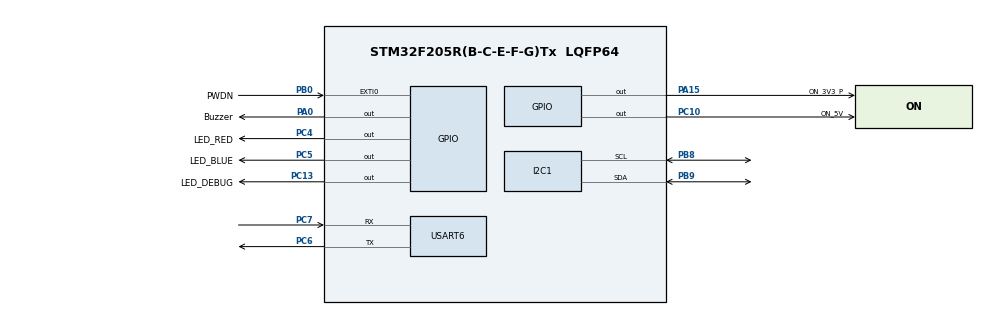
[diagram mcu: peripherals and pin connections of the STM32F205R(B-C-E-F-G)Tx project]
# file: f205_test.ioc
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Dma.Request0=USART6_RX
Dma.Request1=USART6_TX
Dma.USART6_RX.0.Direction=DMA_PERIPH_TO_MEMORY
Dma.USART6_RX.0.FIFOMode=DMA_FIFOMODE_DISABLE
Dma.USART6_RX.0.Instance=DMA2_Stream1
Dma.USART6_RX.0.MemDataAlignment=DMA_MDATAALIGN_BYTE
Dma.USART6_RX.0.MemInc=DMA_MINC_ENABLE
Dma.USART6_RX.0.Mode=DMA_NORMAL
Dma.USART6_RX.0.PeriphDataAlignment=DMA_PDATAALIGN_BYTE
Dma.USART6_RX.0.PeriphInc=DMA_PINC_DISABLE
Dma.USART6_RX.0.Priority=DMA_PRIORITY_LOW
Dma.USART6_TX.1.Direction=DMA_MEMORY_TO_PERIPH
Dma.USART6_TX.1.FIFOMode=DMA_FIFOMODE_DISABLE
Dma.USART6_TX.1.Instance=DMA2_Stream6
Dma.USART6_TX.1.MemDataAlignment=DMA_MDATAALIGN_BYTE
Dma.USART6_TX.1.MemInc=DMA_MINC_ENABLE
Dma.USART6_TX.1.Mode=DMA_NORMAL
Dma.USART6_TX.1.PeriphDataAlignment=DMA_PDATAALIGN_BYTE
Dma.USART6_TX.1.PeriphInc=DMA_PINC_DISABLE
Dma.USART6_TX.1.Priority=DMA_PRIORITY_LOW
Mcu.Family=STM32F2
Mcu.Name=STM32F205R(B-C-E-F-G)Tx
Mcu.Package=LQFP64
NVIC.DMA2_Stream1_IRQn=true\:0\:0\:false\:false\:true\:false\:true\:true
NVIC.DMA2_Stream6_IRQn=true\:0\:0\:false\:false\:true\:false\:true\:true
NVIC.EXTI0_IRQn=true\:0\:0\:false\:false\:true\:true\:true\:true
NVIC.PriorityGroup=NVIC_PRIORITYGROUP_4
PA0-WKUP.GPIO_Label=Buzzer
PA0-WKUP.Signal=GPIO_Output
PA15.GPIO_Label=ON_3V3_P
PA15.Signal=GPIO_Output
PB0.GPIO_Label=PWDN
PB0.Signal=GPXTI0
PB14.Signal=USB_OTG_HS_DM
PB15.Signal=USB_OTG_HS_DP
PB8.GPIO_Pu=GPIO_PULLUP
PB8.Mode=I2C
PB8.Signal=I2C1_SCL
PB9.GPIO_Pu=GPIO_PULLUP
PB9.Mode=I2C
PB9.Signal=I2C1_SDA
PC10.GPIO_Label=ON_5V
PC10.PinState=GPIO_PIN_SET
PC10.Signal=GPIO_Output
PC13.GPIO_Label=LED_DEBUG
PC13.Signal=GPIO_Output
PC4.GPIO_Label=LED_RED
PC4.Signal=GPIO_Output
PC5.GPIO_Label=LED_BLUE
PC5.Signal=GPIO_Output
PC6.Mode=Asynchronous
PC6.Signal=USART6_TX
PC7.Mode=Asynchronous
PC7.Signal=USART6_RX
PH0-OSC_IN.Mode=HSE-External-Oscillator
PH0-OSC_IN.Signal=RCC_OSC_IN
PH1-OSC_OUT.Mode=HSE-External-Oscillator
PH1-OSC_OUT.Signal=RCC_OSC_OUT
ProjectManager.HeapSize=0x200
ProjectManager.StackSize=0x400
ProjectManager.TargetToolchain=Makefile
RCC.48MHZClocksFreq_Value=48000000
RCC.AHBFreq_Value=64000000
RCC.APB1CLKDivider=RCC_HCLK_DIV4
RCC.APB1Freq_Value=16000000
RCC.APB1TimFreq_Value=32000000
RCC.APB2CLKDivider=RCC_HCLK_DIV2
RCC.APB2Freq_Value=32000000
RCC.APB2TimFreq_Value=64000000
RCC.CortexFreq_Value=64000000
RCC.HCLKFreq_Value=64000000
RCC.HSE_VALUE=12000000
RCC.HSI_VALUE=16000000
RCC.LSE_VALUE=32768
RCC.PLLM=6
RCC.PLLP=RCC_PLLP_DIV6
RCC.PLLQ=8
RCC.PLLSourceVirtual=RCC_PLLSOURCE_HSE
RCC.SYSCLKFreq_VALUE=64000000
RCC.SYSCLKSource=RCC_SYSCLKSOURCE_PLLCLK
RCC.VCOOutputFreq_Value=384000000
USART6.VirtualMode=VM_ASYNC
board=custom

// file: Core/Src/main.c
/* USER CODE BEGIN Header */
/**
  ******************************************************************************
  * @file           : main.c
  * @brief          : Main program body
  ******************************************************************************
  * @attention
  *
  * Copyright (c) 2022 STMicroelectronics.
  * All rights reserved.
  *
  * This software is licensed under terms that can be found in the LICENSE file
  * in the root directory of this software component.
  * If no LICENSE file comes with this software, it is provided AS-IS.
  *
  ******************************************************************************
  */
/* USER CODE END Header */
#include "main.h"
#include "dma.h"
#include "i2c.h"
#include "usart.h"
#include "gpio.h"

/* USER CODE BEGIN Includes */
#include "application.h"
/* USER CODE END Includes */

/* USER CODE BEGIN PM */
#define A	142
#define B	126
#define C	213
#define D	210
#define E	190
#define F	178
#define G	211
#define A2	118
/* USER CODE END PM */

void SystemClock_Config(void);

int main(void)
{

  /* MCU Configuration--------------------------------------------------------*/

  /* Reset of all peripherals, Initializes the Flash interface and the Systick. */
  HAL_Init();

  /* Configure the system clock */
  SystemClock_Config();

  /* Initialize all configured peripherals */
  MX_GPIO_Init();
  MX_DMA_Init();
  MX_I2C1_Init();
  MX_USART6_UART_Init();
  /* USER CODE BEGIN 2 */
  application();
  /* USER CODE END 2 */

  /* Infinite loop */
  while (1)
  {

    /* USER CODE BEGIN 3 */
    /* USER CODE BEGIN 3 */
  }
  /* USER CODE END 3 */
}

void SystemClock_Config(void)
{
  LL_FLASH_SetLatency(LL_FLASH_LATENCY_2);
  while(LL_FLASH_GetLatency()!= LL_FLASH_LATENCY_2)
  {
  }
  LL_RCC_HSE_Enable();

   /* Wait till HSE is ready */
  while(LL_RCC_HSE_IsReady() != 1)
  {

  }
  LL_RCC_PLL_ConfigDomain_SYS(LL_RCC_PLLSOURCE_HSE, LL_RCC_PLLM_DIV_6, 192, LL_RCC_PLLP_DIV_6);
  LL_RCC_PLL_Enable();

   /* Wait till PLL is ready */
  while(LL_RCC_PLL_IsReady() != 1)
  {

  }
  LL_RCC_SetAHBPrescaler(LL_RCC_SYSCLK_DIV_1);
  LL_RCC_SetAPB1Prescaler(LL_RCC_APB1_DIV_4);
  LL_RCC_SetAPB2Prescaler(LL_RCC_APB2_DIV_2);
  LL_RCC_SetSysClkSource(LL_RCC_SYS_CLKSOURCE_PLL);

   /* Wait till System clock is ready */
  while(LL_RCC_GetSysClkSource() != LL_RCC_SYS_CLKSOURCE_STATUS_PLL)
  {

  }
  LL_SetSystemCoreClock(64000000);

   /* Update the time base */
  if (HAL_InitTick (TICK_INT_PRIORITY) != HAL_OK)
  {
    Error_Handler();
  }
}

void Error_Handler(void)
{
  __disable_irq();
  while (1)
  {
  }
}
